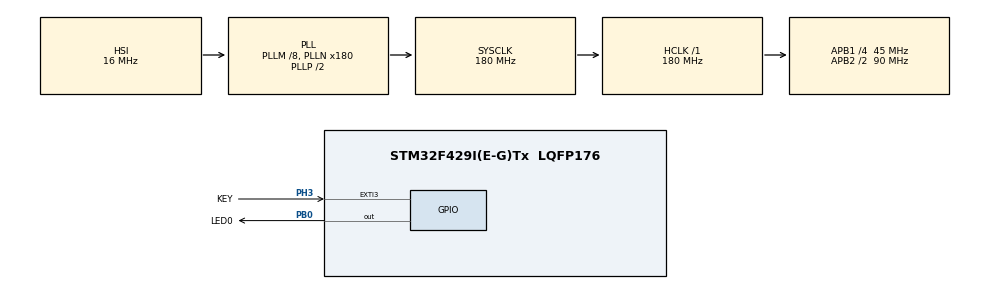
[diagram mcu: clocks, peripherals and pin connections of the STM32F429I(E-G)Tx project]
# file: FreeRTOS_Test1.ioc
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FREERTOS.Tasks01=defaultTask,0,128,StartDefaultTask,Default,NULL,Dynamic,NULL,NULL;myTask02,-3,128,LED_Task,Default,NULL,Dynamic,NULL,NULL
Mcu.Family=STM32F4
Mcu.Name=STM32F429I(E-G)Tx
Mcu.Package=LQFP176
NVIC.EXTI3_IRQn=true\:6\:0\:true\:false\:true\:false\:true\:true\:true
NVIC.PriorityGroup=NVIC_PRIORITYGROUP_4
NVIC.TIM1_UP_TIM10_IRQn=true\:0\:0\:true\:false\:true\:false\:false\:true\:true
NVIC.TimeBase=TIM1_UP_TIM10_IRQn
NVIC.TimeBaseIP=TIM1
PA13.Mode=Serial_Wire
PA13.Signal=SYS_JTMS-SWDIO
PA14.Mode=Serial_Wire
PA14.Signal=SYS_JTCK-SWCLK
PB0.GPIO_Label=LED0
PB0.Signal=GPIO_Output
PH0/OSC_IN.Mode=HSE-External-Oscillator
PH0/OSC_IN.Signal=RCC_OSC_IN
PH1/OSC_OUT.Mode=HSE-External-Oscillator
PH1/OSC_OUT.Signal=RCC_OSC_OUT
PH3.GPIO_Label=KEY
PH3.GPIO_PuPd=GPIO_PULLUP
PH3.Signal=GPXTI3
ProjectManager.HeapSize=0x800
ProjectManager.StackSize=0x800
ProjectManager.TargetToolchain=MDK-ARM V5.27
RCC.48MHZClocksFreq_Value=90000000
RCC.AHBFreq_Value=180000000
RCC.APB1CLKDivider=RCC_HCLK_DIV4
RCC.APB1Freq_Value=45000000
RCC.APB1TimFreq_Value=90000000
RCC.APB2CLKDivider=RCC_HCLK_DIV2
RCC.APB2Freq_Value=90000000
RCC.APB2TimFreq_Value=180000000
RCC.CortexFreq_Value=180000000
RCC.HCLKFreq_Value=180000000
RCC.HSE_VALUE=25000000
RCC.HSI_VALUE=16000000
RCC.LSE_VALUE=32768
RCC.PLLM=8
RCC.PLLN=180
RCC.SYSCLKFreq_VALUE=180000000
RCC.SYSCLKSource=RCC_SYSCLKSOURCE_PLLCLK
RCC.VCOOutputFreq_Value=360000000
VP_FREERTOS_VS_CMSIS_V1.Mode=CMSIS_V1
VP_SYS_VS_tim1.Mode=TIM1
board=custom

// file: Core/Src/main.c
/* USER CODE BEGIN Header */
/**
  ******************************************************************************
  * @file           : main.c
  * @brief          : Main program body
  ******************************************************************************
  * @attention
  *
  * Copyright (c) 2023 STMicroelectronics.
  * All rights reserved.
  *
  * This software is licensed under terms that can be found in the LICENSE file
  * in the root directory of this software component.
  * If no LICENSE file comes with this software, it is provided AS-IS.
  *
  ******************************************************************************
  */
/* USER CODE END Header */
#include "main.h"
#include "cmsis_os.h"
#include "gpio.h"

void SystemClock_Config(void);
void MX_FREERTOS_Init(void);

int main(void)
{

  /* MCU Configuration--------------------------------------------------------*/

  /* Reset of all peripherals, Initializes the Flash interface and the Systick. */
  HAL_Init();

  /* Configure the system clock */
  SystemClock_Config();

  /* Initialize all configured peripherals */
  MX_GPIO_Init();

  /* Call init function for freertos objects (in freertos.c) */
  MX_FREERTOS_Init();

  /* Start scheduler */
  osKernelStart();

  /* We should never get here as control is now taken by the scheduler */
  /* Infinite loop */
  while (1)
  {

  }
}

void SystemClock_Config(void)
{
  RCC_OscInitTypeDef RCC_OscInitStruct = {0};
  RCC_ClkInitTypeDef RCC_ClkInitStruct = {0};

  /** Configure the main internal regulator output voltage
  */
  __HAL_RCC_PWR_CLK_ENABLE();
  __HAL_PWR_VOLTAGESCALING_CONFIG(PWR_REGULATOR_VOLTAGE_SCALE1);

  /** Initializes the RCC Oscillators according to the specified parameters
  * in the RCC_OscInitTypeDef structure.
  */
  RCC_OscInitStruct.OscillatorType = RCC_OSCILLATORTYPE_HSI;
  RCC_OscInitStruct.HSIState = RCC_HSI_ON;
  RCC_OscInitStruct.HSICalibrationValue = RCC_HSICALIBRATION_DEFAULT;
  RCC_OscInitStruct.PLL.PLLState = RCC_PLL_ON;
  RCC_OscInitStruct.PLL.PLLSource = RCC_PLLSOURCE_HSI;
  RCC_OscInitStruct.PLL.PLLM = 8;
  RCC_OscInitStruct.PLL.PLLN = 180;
  RCC_OscInitStruct.PLL.PLLP = RCC_PLLP_DIV2;
  RCC_OscInitStruct.PLL.PLLQ = 4;
  if (HAL_RCC_OscConfig(&RCC_OscInitStruct) != HAL_OK)
  {
    Error_Handler();
  }

  /** Activate the Over-Drive mode
  */
  if (HAL_PWREx_EnableOverDrive() != HAL_OK)
  {
    Error_Handler();
  }

  /** Initializes the CPU, AHB and APB buses clocks
  */
  RCC_ClkInitStruct.ClockType = RCC_CLOCKTYPE_HCLK|RCC_CLOCKTYPE_SYSCLK
                              |RCC_CLOCKTYPE_PCLK1|RCC_CLOCKTYPE_PCLK2;
  RCC_ClkInitStruct.SYSCLKSource = RCC_SYSCLKSOURCE_PLLCLK;
  RCC_ClkInitStruct.AHBCLKDivider = RCC_SYSCLK_DIV1;
  RCC_ClkInitStruct.APB1CLKDivider = RCC_HCLK_DIV4;
  RCC_ClkInitStruct.APB2CLKDivider = RCC_HCLK_DIV2;

  if (HAL_RCC_ClockConfig(&RCC_ClkInitStruct, FLASH_LATENCY_5) != HAL_OK)
  {
    Error_Handler();
  }
}

void HAL_TIM_PeriodElapsedCallback(TIM_HandleTypeDef *htim)
{
  if (htim->Instance == TIM1) {
    HAL_IncTick();
  }
}

void Error_Handler(void)
{
  __disable_irq();
  while (1)
  {
  }
}

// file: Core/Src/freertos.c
/* USER CODE BEGIN Header */
/**
  ******************************************************************************
  * File Name          : freertos.c
  * Description        : Code for freertos applications
  ******************************************************************************
  * @attention
  *
  * Copyright (c) 2023 STMicroelectronics.
  * All rights reserved.
  *
  * This software is licensed under terms that can be found in the LICENSE file
  * in the root directory of this software component.
  * If no LICENSE file comes with this software, it is provided AS-IS.
  *
  ******************************************************************************
  */
/* USER CODE END Header */

#include "FreeRTOS.h"
#include "task.h"
#include "main.h"
#include "cmsis_os.h"

osThreadId defaultTaskHandle;
osThreadId myTask02Handle;

void StartDefaultTask(void const * argument);
void LED_Task(void const * argument);

void MX_FREERTOS_Init(void); /* (MISRA C 2004 rule 8.1) */

/* GetIdleTaskMemory prototype (linked to static allocation support) */
void vApplicationGetIdleTaskMemory( StaticTask_t **ppxIdleTaskTCBBuffer, StackType_t **ppxIdleTaskStackBuffer, uint32_t *pulIdleTaskStackSize );

/* USER CODE BEGIN GET_IDLE_TASK_MEMORY */
static StaticTask_t xIdleTaskTCBBuffer;
static StackType_t xIdleStack[configMINIMAL_STACK_SIZE];

void vApplicationGetIdleTaskMemory( StaticTask_t **ppxIdleTaskTCBBuffer, StackType_t **ppxIdleTaskStackBuffer, uint32_t *pulIdleTaskStackSize )
{
  *ppxIdleTaskTCBBuffer = &xIdleTaskTCBBuffer;
  *ppxIdleTaskStackBuffer = &xIdleStack[0];
  *pulIdleTaskStackSize = configMINIMAL_STACK_SIZE;
  /* place for user code */
}
/* USER CODE END GET_IDLE_TASK_MEMORY */

void MX_FREERTOS_Init(void) {

  /* Create the thread(s) */
  /* definition and creation of defaultTask */
  osThreadDef(defaultTask, StartDefaultTask, osPriorityNormal, 0, 128);
  defaultTaskHandle = osThreadCreate(osThread(defaultTask), NULL);

  /* definition and creation of myTask02 */
  osThreadDef(myTask02, LED_Task, osPriorityIdle, 0, 128);
  myTask02Handle = osThreadCreate(osThread(myTask02), NULL);

}

void StartDefaultTask(void const * argument)
{
  for(;;)
  {
    osDelay(1);
  }
}

void LED_Task(void const * argument)
{
  /* USER CODE BEGIN LED_Task */
    static uint8_t count = 0;
    uint32_t NotifyValue;
    BaseType_t err;
  /* Infinite loop */
  for(;;)
  {
      err = xTaskNotifyWait(0x00, 0xFFFFFFFF, &NotifyValue, portMAX_DELAY);

      if(err == pdPASS)
      {
          if((NotifyValue & 0x01) != 0)
          {
              if(count == 1)
              {
                  HAL_GPIO_WritePin(LED0_GPIO_Port, LED0_Pin, 1);
                  count = 0;
              }
              else
              {
                  HAL_GPIO_WritePin(LED0_GPIO_Port, LED0_Pin, 0);
                  count = 1;
              }
          }
      }

//      HAL_GPIO_TogglePin(LED0_GPIO_Port, LED0_Pin);
//    osDelay(500);

//      count++;
//      if(count > 3)
//      {
//          count = 0;
//          vTaskSuspend(NULL);
//      }
  }
  /* USER CODE END LED_Task */
}

/* USER CODE BEGIN Application */
void HAL_GPIO_EXTI_Callback(uint16_t GPIO_Pin)
{
    BaseType_t YieldRequired;
    if(GPIO_Pin == KEY_Pin)
    {
            xTaskNotifyFromISR(myTask02Handle, 0x01, eSetBits, &YieldRequired);
//        YieldRequired = xTaskResumeFromISR(myTask02Handle);
//        if(YieldRequired == pdTRUE)
//        {
//            portYIELD_FROM_ISR(YieldRequired);
//        }
    }
}
/* USER CODE END Application */
